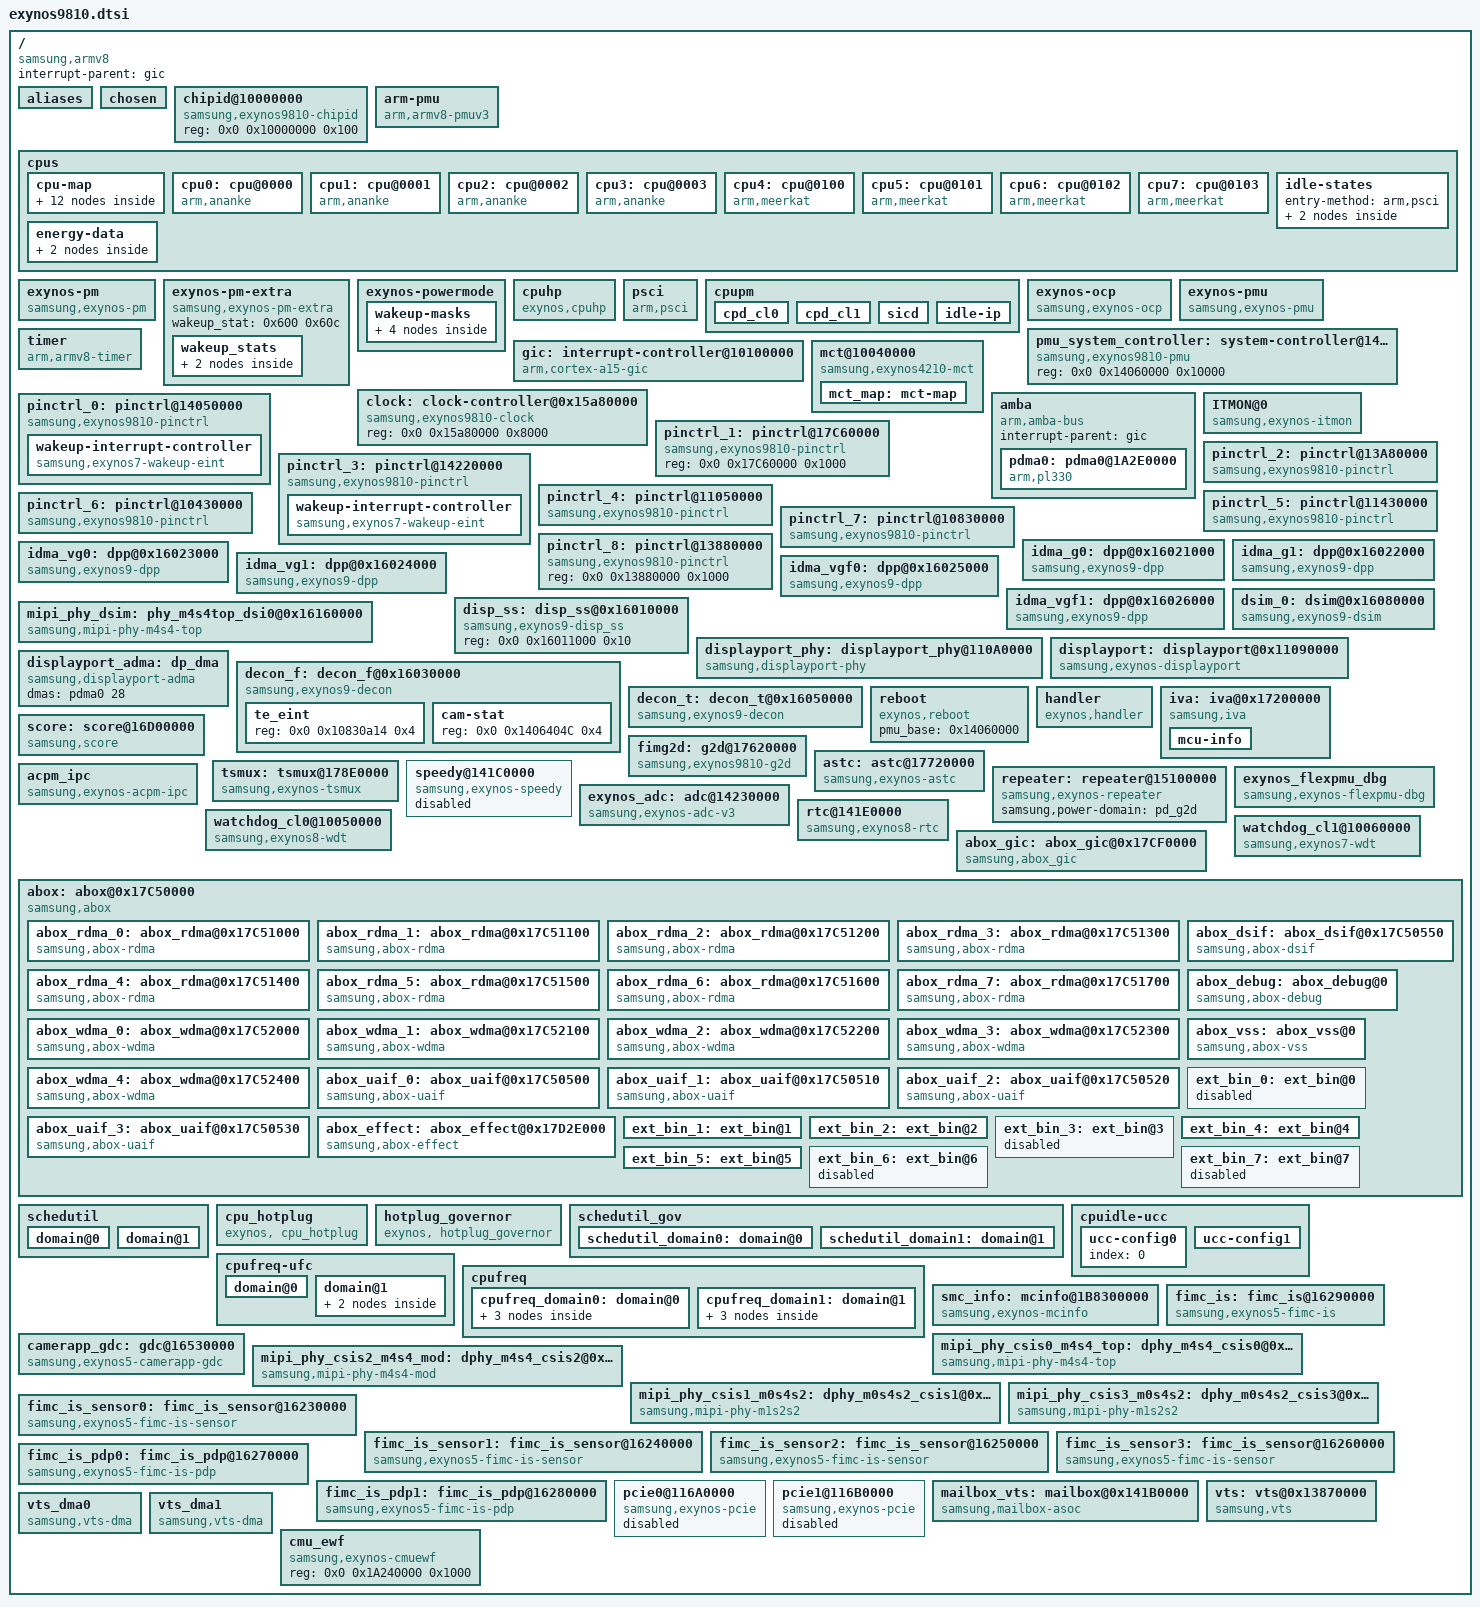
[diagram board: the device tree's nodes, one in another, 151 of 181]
/*
 * SAMSUNG EXYNOS9810 SoC device tree source
 *
 * Copyright (c) 2017 Samsung Electronics Co., Ltd.
 *		http://www.samsung.com
 *
 * SAMSUNG EXYNOS9810 SoC device nodes are listed in this file.
 * EXYNOS9810 based board files can include this file and provide
 * values for board specfic bindings.
 *
 * This program is free software; you can redistribute it and/or modify
 * it under the terms of the GNU General Public License version 2 as
 * published by the Free Software Foundation.
 */

#include <dt-bindings/clock/exynos9810.h>
#include <dt-bindings/interrupt-controller/exynos9810.h>
#include <dt-bindings/sysmmu/sysmmu.h>
#include <dt-bindings/soc/samsung/exynos9810.h>
#include <dt-bindings/thermal/thermal.h>
#include <dt-bindings/camera/fimc_is.h>
#include <dt-bindings/pci/pci.h>
#include <dt-bindings/ufs/ufs.h>
#include "exynos9810-pinctrl.dtsi"
#include "exynos9810-pm-domains.dtsi"
#include "exynos9810-etm.dtsi"
//#include "exynos9810-inputbooster.dtsi"
#include "exynos9810-debug.dtsi"
#include "exynos9810-mfc.dtsi"
#include "exynos9810-ufs.dtsi"
#include "exynos9810-security.dtsi"
#include "exynos9810-dm.dtsi"
#include "exynos9810-usb.dtsi"
#include "exynos9810-thermal.dtsi"
#include "exynos9810-pwm.dtsi"
#include "exynos9810-mmc.dtsi"
#include "exynos9810-devfreq.dtsi"
#include "exynos9810-power.dtsi"
#include "exynos9810-m2m.dtsi"
#include "exynos9810-gpu.dtsi"
#include "exynos9810-ems.dtsi"
#include "exynos9810-usi.dtsi"
#include "exynos9810-sysmmu.dtsi"

/ {
	compatible = "samsung,armv8", "samsung,exynos9810";
	interrupt-parent = <&gic>;
	#address-cells = <2>;
	#size-cells = <1>;

	aliases {
		pinctrl0 = &pinctrl_0;
		pinctrl1 = &pinctrl_1;
		pinctrl2 = &pinctrl_2;
		pinctrl3 = &pinctrl_3;
		pinctrl4 = &pinctrl_4;
		pinctrl5 = &pinctrl_5;
		pinctrl6 = &pinctrl_6;
		pinctrl7 = &pinctrl_7;
		pinctrl8 = &pinctrl_8;
		dpp0 = &idma_g0;
		dpp1 = &idma_g1;
		dpp2 = &idma_vg0;
		dpp3 = &idma_vg1;
		dpp4 = &idma_vgf0;
		dpp5 = &idma_vgf1;
		dsim0 = &dsim_0;
		displayport = &displayport;
		decon0 = &decon_f;
		decon2 = &decon_t;
		mfc0 = &mfc_0;
	};

	chosen: chosen {
		bootargs = "";
		linux,initrd-start = <0x84000000>;
		linux,initrd-end = <0x841FFFFF>;
	};

	chipid@10000000 {
		compatible = "samsung,exynos9810-chipid";
		reg = <0x0 0x10000000 0x100>;
	};

	arm-pmu {
		compatible = "arm,armv8-pmuv3";
		interrupts = <0 INTREQ__CPUCL1_PMUIRQ_0 4>,
			     <0 INTREQ__CPUCL1_PMUIRQ_1 4>,
			     <0 INTREQ__CPUCL1_PMUIRQ_2 4>,
			     <0 INTREQ__CPUCL1_PMUIRQ_3 4>,
			     <0 INTREQ__CPUCL0_PMUIRQ_0 4>,
			     <0 INTREQ__CPUCL0_PMUIRQ_1 4>,
			     <0 INTREQ__CPUCL0_PMUIRQ_2 4>,
			     <0 INTREQ__CPUCL0_PMUIRQ_3 4>;

		interrupt-affinity = <&cpu4>,
					<&cpu5>,
					<&cpu6>,
					<&cpu7>,
					<&cpu0>,
					<&cpu1>,
					<&cpu2>,
					<&cpu3>;			     
	};

	cpus {
		#address-cells = <2>;
		#size-cells = <0>;

		cpu-map {
			cluster0 {
				coregroup0 {
					core0 {
						cpu = <&cpu0>;
					};
					core1 {
						cpu = <&cpu1>;
					};
					core2 {
						cpu = <&cpu2>;
					};
					core3 {
						cpu = <&cpu3>;
					};
				};
			};

			cluster1 {
				coregroup0 {
					core0 {
						cpu = <&cpu4>;
					};
					core1 {
						cpu = <&cpu5>;
					};
					core2 {
						cpu = <&cpu6>;
					};
					core3 {
						cpu = <&cpu7>;
					};
				};
			};
		};

		cpu0: cpu@0000 {
			device_type = "cpu";
			compatible = "arm,ananke", "arm,armv8";
			reg = <0x0 0x0000>;
			enable-method = "psci";
			cpu-idle-states = <&BOOTCL_CPU_SLEEP>;
			sched-energy-data = <&ANANKE_ENERGY>;
		};
		cpu1: cpu@0001 {
			device_type = "cpu";
			compatible = "arm,ananke", "arm,armv8";
			reg = <0x0 0x0001>;
			enable-method = "psci";
			cpu-idle-states = <&BOOTCL_CPU_SLEEP>;
			sched-energy-data = <&ANANKE_ENERGY>;
		};
		cpu2: cpu@0002 {
			device_type = "cpu";
			compatible = "arm,ananke", "arm,armv8";
			reg = <0x0 0x0002>;
			enable-method = "psci";
			cpu-idle-states = <&BOOTCL_CPU_SLEEP>;
			sched-energy-data = <&ANANKE_ENERGY>;
		};
		cpu3: cpu@0003 {
			device_type = "cpu";
			compatible = "arm,ananke", "arm,armv8";
			reg = <0x0 0x0003>;
			enable-method = "psci";
			cpu-idle-states = <&BOOTCL_CPU_SLEEP>;
			sched-energy-data = <&ANANKE_ENERGY>;
		};
		cpu4: cpu@0100 {
			device_type = "cpu";
			compatible = "arm,meerkat", "arm,armv8";
			reg = <0x0 0x100>;
			enable-method = "psci";
			cpu-idle-states = <&NONBOOTCL_CPU_SLEEP>;
			sched-energy-data = <&MEERKAT_ENERGY>;
		};
		cpu5: cpu@0101 {
			device_type = "cpu";
			compatible = "arm,meerkat", "arm,armv8";
			reg = <0x0 0x101>;
			enable-method = "psci";
			cpu-idle-states = <&NONBOOTCL_CPU_SLEEP>;
			sched-energy-data = <&MEERKAT_ENERGY>;
		};
		cpu6: cpu@0102 {
			device_type = "cpu";
			compatible = "arm,meerkat", "arm,armv8";
			reg = <0x0 0x102>;
			enable-method = "psci";
			cpu-idle-states = <&NONBOOTCL_CPU_SLEEP>;
			sched-energy-data = <&MEERKAT_ENERGY>;
		};
		cpu7: cpu@0103 {
			device_type = "cpu";
			compatible = "arm,meerkat", "arm,armv8";
			reg = <0x0 0x103>;
			enable-method = "psci";
			cpu-idle-states = <&NONBOOTCL_CPU_SLEEP>;
			sched-energy-data = <&MEERKAT_ENERGY>;
		};
		idle-states {
			entry-method = "arm,psci";

			BOOTCL_CPU_SLEEP: bootcl-cpu-sleep {
				idle-state-name = "c2";
				compatible = "exynos,idle-state";
				arm,psci-suspend-param = <0x0010000>;
				entry-latency-us = <70>;
				exit-latency-us = <160>;
				min-residency-us = <2000>;
				status = "okay";
			};

			NONBOOTCL_CPU_SLEEP: nobootcl-cpu-sleep {
				idle-state-name = "c2";
				compatible = "exynos,idle-state";
				arm,psci-suspend-param = <0x0010000>;
				entry-latency-us = <235>;
				exit-latency-us = <220>;
				min-residency-us = <3500>;
				status = "okay";
			};
		};

		energy-data {
			ANANKE_ENERGY: ananke-energy {
				mips-per-mhz = <2776>;
				capacity-mips = <272>;
				power-coefficient = <160>;
				capacity-mips-s = <215>;
				power-coefficient-s = <130>;
				static-power-coefficient = <45>;

				capacity-weight = <1>;
				energy-weight = <1>;
			};
			MEERKAT_ENERGY: meerkat-energy {
				mips-per-mhz = <8012>;
				capacity-mips = <785>;
				power-coefficient = <800>;
				capacity-mips-s = <365>;
				power-coefficient-s = <506>;
				static-power-coefficient = <120>;

				capacity-weight = <1>;
				energy-weight = <3>;
			};
		};
	};

	exynos-pm {
		compatible = "samsung,exynos-pm";
		reg = <0x0 0x14050000 0x1000>,
		    <0x0 0x10101200 0x100>;
		reg-names = "gpio_alive_base",
				"gicd_ispendrn_base";
		num-eint = <34>;
		num-gic = <16>;
		suspend_mode_idx = <8>;		/* SYS_SLEEP */
		suspend_psci_idx = <133>;	/* PSCI_SYSTEM_SLEEP */
		cp_call_mode_idx = <10>;	/* SYS_SLEEP_AUD_ON */
		cp_call_psci_idx = <133>;	/* PSCI_SYSTEM_SLEEP */

		usbl2_suspend_available = <1>;	/* SYS_SLEEP_AUD_ON */
		usbl2_suspend_mode_idx = <12>;	/* SYS_SLEEP_AUD_ON */
		conn_req_offset = <0x00c0>;	/* PMU_ALIVE__CONNECT_REQ_STATUS */
	};

	exynos-pm-extra {
		compatible = "samsung,exynos-pm-extra";
		wakeup_stat = <0x600 0x60c>;

		wakeup_stats {
			wakeup_stat {
				ws-name =
					"RTC_ALARM",		/* [ 0] */
					"RTC_TICK",		/* [ 1] */
					"TRTC_ALARM",		/* [ 2] */
					"TRTC_TICK",		/* [ 3] */
					"SPARE",		/* [ 4] */
					"CMGP2PMU_AP_EINT0",	/* [ 5] */
					"CMGP2PMU_AP_EINT1",	/* [ 6] */
					"MAILBOX_APM2AP",	/* [ 7] */
					"MAILBOX_CP2AP",	/* [ 8] */
					"MAILBOX_VTS2AP",	/* [ 9] */
					"S_MAILBOX_CP2AP",	/* [10] */
					"VTS_WDT",		/* [11] */
					"EINT",			/* [12] */
					"EXT_PCIE_GEN2",	/* [13] */
					"PCIE_GEN2",		/* [14] */
					"USB_REWA",		/* [15] */
					"USBDP",		/* [16] */
					"MMC_CARD",		/* [17] */
					"TIMER";		/* [18] */
			};
			wakeup2_stat {
				ws-name =
					"UART_BT_CTSn",		/* [ 0] */
					"UART_BT_RXD",		/* [ 1] */
					"USB20_PHY_FS_VMINUS",	/* [ 2] */
					"USB20_PHY_FS_VPLUS";	/* [ 3] */
			};
		};
	};

	exynos-powermode {
		wakeup-masks {
			/*
			 * wakeup_mask configuration
			 *	        SICD          SICD_CPD      AFTR          STOP
			 *              LPD           LPA           ALPA          DSTOP
			 *              SLEEP         SLEEP_VTS_ON  SLEEP_AUD_ON  FAPO USB_L2
			 */
			wakeup-mask {
				mask = <0x400001E0>, <0x0>,        <0x0>,        <0x0>,
				       <0x0>,        <0x0>,        <0x0>,        <0x0>,
				       <0xD00F7E7E>, <0x500F7E7E>, <0x500F7E7E>, <0x0>, <0xD00D7E7E>;
				reg-offset = <0x610>;
			};
			wakeup-mask2 {
				mask = <0x0>,	     <0x0>, 	   <0x0>, 	 <0x0>,
				       <0x0>,        <0x0>,        <0x0>,        <0x0>,
				       <0xFFFF00FF>, <0xFFFF00FF>, <0xFFFF00FF>, <0x0>, <0xFFFF00FF>;
				reg-offset = <0x614>;
			};
			wakeup-mask3 {
				mask = <0x0>,	     <0x0>, 	   <0x0>, 	 <0x0>,
				       <0x0>,        <0x0>,        <0x0>,        <0x0>,
				       <0xFFFF00FF>, <0xFFFF00FF>, <0xFFFF00FF>, <0x0>, <0xFFFF00FF>;
				reg-offset = <0x618>;
			};
			wakeup-mask4 {
				mask = <0x0>,	     <0x0>, 	   <0x0>,	 <0x0>,
				       <0x0>,        <0x0>,        <0x0>,        <0x0>,
				       <0x0>, 	     <0x0>, 	   <0x0>,        <0x0>, <0x0>;
				reg-offset = <0x644>;
			};
		};
	};

	cpuhp {
		compatible = "exynos,cpuhp";
	};

	psci {
		compatible = "arm,psci";
		method = "smc";
		cpu_suspend = <0xC4000001>;
		cpu_off = <0x84000002>;
		cpu_on = <0xC4000003>;
	};

	cpupm {
		#define POWERMODE_TYPE_CLUSTER	0
		#define POWERMODE_TYPE_SYSTEM	1

		cpd_cl0 {
			device_type = "cpupm";
			target-residency = <10000>;
			psci-index = <128>;
			type = <POWERMODE_TYPE_CLUSTER>;
			siblings = "0-3";
		};

		cpd_cl1 {
			device_type = "cpupm";
			target-residency = <10000>;
			psci-index = <128>;
			type = <POWERMODE_TYPE_CLUSTER>;
			siblings = "4-7";
			entry-allowed = "4-7";
		};

		sicd {
			device_type = "cpupm";
			target-residency = <10000>;	/* us */
			psci-index = <256>;
			type = <POWERMODE_TYPE_SYSTEM>;
			siblings = "0-7";
			entry-allowed = "0-3";
			system-idle;
		};

		idle-ip {
			idle-ip-list =
				  "104c0000.pwm",		/* [ 0] pwm      */
			          "14230000.adc",		/* [ 1] adc      */
			          "10860000.hsi2c",		/* [ 2] hsi2c_0  */
			          "10870000.hsi2c",		/* [ 3] hsi2c_1  */
			          "10880000.hsi2c",		/* [ 4] hsi2c_2  */
			          "10890000.hsi2c",		/* [ 5] hsi2c_3  */
			          "10450000.hsi2c",		/* [ 6] hsi2c_4  */
			          "10460000.hsi2c",		/* [ 7] hsi2c_5  */
			          "10470000.hsi2c",		/* [ 8] hsi2c_6  */
			          "10480000.hsi2c",		/* [ 9] hsi2c_7  */
			          "10490000.hsi2c",		/* [10] hsi2c_8  */
			          "104a0000.hsi2c",		/* [11] hsi2c_9  */
			          "104b0000.hsi2c",		/* [12] hsi2c_10 */
			          "104c0000.hsi2c",		/* [13] hsi2c_11 */
			          "104d0000.hsi2c",		/* [14] hsi2c_12 */
			          "104e0000.hsi2c",		/* [15] hsi2c_13 */
			          "104f0000.hsi2c",		/* [16] hsi2c_14 */
			          "10500000.hsi2c",		/* [17] hsi2c_15 */
			          "108a0000.hsi2c",		/* [18] hsi2c_16 */
			          "108b0000.hsi2c",		/* [19] hsi2c_17 */
			          "108c0000.hsi2c",		/* [20] hsi2c_18 */
			          "108d0000.hsi2c",		/* [21] hsi2c_19 */
			          "108e0000.hsi2c",		/* [22] hsi2c_20 */
			          "108f0000.hsi2c",		/* [23] hsi2c_21 */
			          "10900000.hsi2c",		/* [24] hsi2c_22 */
			          "10910000.hsi2c",		/* [25] hsi2c_23 */
			          "10920000.hsi2c",		/* [26] hsi2c_24 */
			          "10930000.hsi2c",		/* [27] hsi2c_25 */
			          "10940000.hsi2c",		/* [28] hsi2c_26 */
			          "10950000.hsi2c",		/* [29] hsi2c_27 */
			          "10520000.hsi2c",		/* [30] hsi2c_28 */
			          "10530000.hsi2c",		/* [31] hsi2c_29 */
			          "10540000.hsi2c",		/* [32] hsi2c_30 */
			          "10550000.hsi2c",		/* [33] hsi2c_31 */
			          "10560000.hsi2c",		/* [34] hsi2c_32 */
			          "10570000.hsi2c",		/* [35] hsi2c_33 */
			          "14300000.hsi2c",		/* [36] hsi2c_34 */
			          "14310000.hsi2c",		/* [37] hsi2c_35 */
			          "14320000.hsi2c",		/* [38] hsi2c_36 */
			          "14330000.hsi2c",		/* [39] hsi2c_37 */
			          "14340000.hsi2c",		/* [40] hsi2c_38 */
			          "14350000.hsi2c",		/* [41] hsi2c_39 */
			          "14360000.hsi2c",		/* [42] hsi2c_40 */
			          "14370000.hsi2c",		/* [43] hsi2c_41 */
			          "10850000.spi",		/* [44] spi_0    */
			          "10450000.spi",		/* [45] spi_1    */
			          "10470000.spi",		/* [46] spi_2    */
			          "10490000.spi",		/* [47] spi_3    */
			          "104b0000.spi",		/* [48] spi_4    */
			          "104d0000.spi",		/* [49] spi_5    */
			          "104f0000.spi",		/* [50] spi_6    */
			          "108a0000.spi",		/* [51] spi_7    */
			          "108c0000.spi",		/* [52] spi_8    */
			          "108e0000.spi",		/* [53] spi_9    */
			          "10900000.spi",		/* [54] spi_10   */
			          "10920000.spi",		/* [55] spi_11   */
			          "10940000.spi",		/* [56] spi_12   */
			          "10520000.spi",		/* [57] spi_13   */
			          "10540000.spi",		/* [58] spi_14   */
			          "10560000.spi",		/* [59] spi_15   */
			          "14300000.spi",		/* [60] spi_16   */
			          "14320000.spi",		/* [61] spi_17   */
			          "14340000.spi",		/* [62] spi_18   */
			          "14360000.spi",		/* [63] spi_19   */
			          "11120000.ufs",		/* [64] ufs      */
			          "11500000.dwmmc2",		/* [65] dwmmc2   */
			          "10c00000.usb",		/* [66] usb      */
			          "141a0000.mailbox",		/* [67] mailbox  */
			          "116a0000.pcie0",		/* [68] pcie0    */
			          "116b0000.pcie1",		/* [69] pcie1    */
			          "pd-aud",			/* [70] pd-aud	 */
			          "pd-dcf",			/* [71] pd-dcf   */
			          "pd-dcpost",			/* [72] pd-dcpost*/
			          "pd-dcrd",			/* [73] pd-dcrd  */
			          "pd-dpu",			/* [74] pd-dpu   */
			          "pd-dspm",			/* [75] pd-dspm  */
			          "pd-dsps",			/* [76] pd-dsps  */
			          "pd-g2d",			/* [77] pd-g2d   */
			          "pd-embedded_g3d",		/* [78] pd-embedded_g3d */
			          "pd-isppre",			/* [79] pd-isppre */
			          "pd-isphq",			/* [80] pd-isphq */
			          "pd-isplp",			/* [81] pd-isplp */
			          "pd-iva",			/* [82] pd-iva   */
			          "pd-mfc",			/* [83] pd-mfc   */
			          "pd-vts",			/* [84] pd-vts   */
			          "11090000.displayport",	/* [85] displayport */
			          "bluetooth";			/* [86] bluetooth */

			fix-idle-ip = "acpm_dvfs";
			fix-idle-ip-index = <96>;

			idle-ip-mask = <0>,  <1>,  <2>,  <3>,  <4>,  <5>,  <6>,  <7>,  <8>,  <9>,
					     <10>, <11>, <12>, <13>, <14>, <15>, <16>, <17>, <18>, <19>,
					     <20>, <21>, <22>, <23>, <24>, <25>, <26>, <27>, <28>, <29>,
					     <30>, <31>, <32>, <33>, <34>, <35>, <36>, <37>, <38>, <39>,
					     <40>, <41>, <42>, <43>, <44>, <45>, <46>, <47>, <48>, <49>,
					     <50>, <51>, <52>, <53>, <54>, <55>, <56>, <57>, <58>, <59>,
					     <60>, <61>, <62>, <63>, <64>, <65>, <66>, <67>, <68>, <69>,
					                             <74>, <75>, <76>, <77>, <78>, <79>,
					     <80>, <81>, <82>, <83>,       <85>, <86>, <96>;
		};
	};

	exynos-ocp {
		compatible = "samsung,exynos-ocp";

		interrupts = <0 INTREQ__CPUCL1_GCUIRQ 0>;
		sibling-cpus = "4-7";
		down-step = <1>;

		max-freq-wo-ocp = <1794000>;

		release-mode = <1>;		/* 0 : current meter, 1 : cpu utilization */
		release-threshold = <50>;	/* @current meter : current(A), @cpu load : capacity ratio(%) */
		release-duration = <15>;	/* msec */
	};

	exynos-pmu {
		compatible = "samsung,exynos-pmu";
		samsung,syscon-phandle = <&pmu_system_controller>;
		reg = <0x0 0x14060000 0x10000>;
		reg-names = "pmu_alive";
	};

	pmu_system_controller: system-controller@14060000 {
		compatible = "samsung,exynos9810-pmu", "syscon";
		reg = <0x0 0x14060000 0x10000>;
	};

	gic:interrupt-controller@10100000 {
		compatible = "arm,cortex-a15-gic", "arm,cortex-a9-gic";
		#interrupt-cells = <3>;
		#address-cells = <0>;
		interrupt-controller;
		reg =	<0x0 0x10101000 0x1000>,
			<0x0 0x10102000 0x1000>,
			<0x0 0x10104000 0x2000>,
			<0x0 0x10106000 0x2000>;
		interrupts = <1 9 0xf04>;
	};

	timer {
		compatible = "arm,armv8-timer";
		interrupts = <GIC_PPI 13
				(GIC_CPU_MASK_SIMPLE(8) | IRQ_TYPE_LEVEL_LOW)>,
			     <GIC_PPI 14
				(GIC_CPU_MASK_SIMPLE(8) | IRQ_TYPE_LEVEL_LOW)>,
			     <GIC_PPI 11
				(GIC_CPU_MASK_SIMPLE(8) | IRQ_TYPE_LEVEL_LOW)>,
			     <GIC_PPI 10
				(GIC_CPU_MASK_SIMPLE(8) | IRQ_TYPE_LEVEL_LOW)>;
	        clock-frequency = <26000000>;
		use-clocksource-only;
		use-physical-timer;
	};

	clock: clock-controller@0x15a80000 {
		compatible = "samsung,exynos9810-clock";
		reg = <0x0 0x15a80000 0x8000>;
		#clock-cells = <1>;
	};

	mct@10040000 {
		compatible = "samsung,exynos4210-mct";
		reg = <0x0 0x10040000 0x800>;
		interrupt-controller;
		#interrupt-cells = <1>;
		interrupt-parent = <&mct_map>;
		interrupts =	<0>, <1>, <2>, <3>,
				<4>, <5>, <6>, <7>,
				<8>, <9>, <10>, <11>;
		clocks = <&clock OSCCLK>, <&clock GATE_MCT>;
		clock-names = "fin_pll", "mct";
		use-clockevent-only;

		mct_map: mct-map {
			#interrupt-cells = <1>;
			#address-cells = <0>;
			#size-cells = <0>;
			interrupt-map = <0 &gic 0 INTREQ__MCT_G0 0>,
					<1 &gic 0 INTREQ__MCT_G1 0>,
					<2 &gic 0 INTREQ__MCT_G2 0>,
					<3 &gic 0 INTREQ__MCT_G3 0>,
					<4 &gic 0 INTREQ__MCT_L0 0>,
					<5 &gic 0 INTREQ__MCT_L1 0>,
					<6 &gic 0 INTREQ__MCT_L2 0>,
					<7 &gic 0 INTREQ__MCT_L3 0>,
					<8 &gic 0 INTREQ__MCT_L4 0>,
					<9 &gic 0 INTREQ__MCT_L5 0>,
					<10 &gic 0 INTREQ__MCT_L6 0>,
					<11 &gic 0 INTREQ__MCT_L7 0>;
		};
	};

	/* DMA */
	amba {
		#address-cells = <2>;
		#size-cells = <1>;
		compatible = "arm,amba-bus";
		interrupt-parent = <&gic>;
		ranges;

		pdma0: pdma0@1A2E0000 {
			compatible = "arm,pl330", "arm,primecell";
			reg = <0x0 0x1A2E0000 0x1000>;
			interrupts = <0 INTREQ__PDMA0 0>;
			clocks = <&clock GATE_PDMA0>;
			clock-names = "apb_pclk";
			#dma-cells = <1>;
			#dma-channels = <8>;
			#dma-requests = <32>;
			#dma-multi-irq = <1>;
			dma-arwrapper = <0x1A2E4400>,
					<0x1A2E4420>,
					<0x1A2E4440>,
					<0x1A2E4460>,
					<0x1A2E4480>,
					<0x1A2E44A0>,
					<0x1A2E44C0>,
					<0x1A2E44E0>;
			dma-awwrapper = <0x1A2E4404>,
					<0x1A2E4424>,
					<0x1A2E4444>,
					<0x1A2E4464>,
					<0x1A2E4484>,
					<0x1A2E44A4>,
					<0x1A2E44C4>,
					<0x1A2E44E4>;
			dma-instwrapper = <0x1A2E4500>;
			dma-mask-bit = <36>;
			coherent-mask-bit = <36>;
		};
	};

	ITMON@0 {
		compatible = "samsung,exynos-itmon";
		interrupts = <0 INTREQ__TREX_DEBUG 0>,  /* DATA_BUS_C  */
			     <0 INTREQ__TREX_D_CORE_debugInterrupt 0>, /* DATA_CORE   */
			     <0 INTREQ__TREX_P0_CORE_debugInterrupt 0>, /* PERI_CORE_0 */
			     <0 INTREQ__TREX_P_DEBUG 0>,  /* PERI_BUS_C  */
			     <0 INTREQ__TREX_P1_CORE_debugInterrupt 0>, /* PERI_CORE_1 */
			     <0 INTREQ__TREX_P_BUS1_DEBUG 0>;  /* PERI_BUS_1  */
	};

	/* ALIVE */
	pinctrl_0: pinctrl@14050000 {
		compatible = "samsung,exynos9810-pinctrl";
		reg = <0x0 0x14050000 0x1000>;
		interrupts = <0 INTREQ__EINT0 0>, <0 INTREQ__EINT1 0>, <0 INTREQ__EINT2 0>,
			     <0 INTREQ__EINT3 0>, <0 INTREQ__EINT4 0>, <0 INTREQ__EINT5 0>,
			     <0 INTREQ__EINT6 0>, <0 INTREQ__EINT7 0>, <0 INTREQ__EINT8 0>,
			     <0 INTREQ__EINT9 0>, <0 INTREQ__EINT10 0>, <0 INTREQ__EINT11 0>,
			     <0 INTREQ__EINT12 0>, <0 INTREQ__EINT13 0>, <0 INTREQ__EINT14 0>,
			     <0 INTREQ__EINT15 0>, <0 INTREQ__EINT16 0>, <0 INTREQ__EINT17 0>,
			     <0 INTREQ__EINT18 0>, <0 INTREQ__EINT19 0>, <0 INTREQ__EINT20 0>,
			     <0 INTREQ__EINT21 0>, <0 INTREQ__EINT22 0>, <0 INTREQ__EINT23 0>,
			     <0 INTREQ__EINT24 0>, <0 INTREQ__EINT25 0>, <0 INTREQ__EINT26 0>,
			     <0 INTREQ__EINT27 0>, <0 INTREQ__EINT28 0>, <0 INTREQ__EINT29 0>,
			     <0 INTREQ__EINT30 0>, <0 INTREQ__EINT31 0>, <0 INTREQ__EINT32 0>,
			     <0 INTREQ__EINT33 0>;

		wakeup-interrupt-controller {
			compatible = "samsung,exynos7-wakeup-eint";
		};
	};

	/* AUD */
	pinctrl_1: pinctrl@17C60000{
		compatible = "samsung,exynos9810-pinctrl";
		reg = <0x0 0x17C60000 0x1000>;
	};

	/* CHUB */
	pinctrl_2: pinctrl@13A80000{
		compatible = "samsung,exynos9810-pinctrl";
		reg = <0x0 0x13A80000 0x1000>;
		interrupts = <0 INTREQ__GPIO_CHUB 0>;
	};

	/* CMGP */
	pinctrl_3: pinctrl@14220000{
		compatible = "samsung,exynos9810-pinctrl";
		reg = <0x0 0x14220000 0x1000>;
		interrupts = <0 INTREQ__EXT_INTM0_0 0>, <0 INTREQ__EXT_INTM0_1 0>,
			     <0 INTREQ__EXT_INTM0_2 0>, <0 INTREQ__EXT_INTM0_3 0>,
			     <0 INTREQ__EXT_INTM0_4 0>, <0 INTREQ__EXT_INTM0_5 0>,
			     <0 INTREQ__EXT_INTM0_6 0>, <0 INTREQ__EXT_INTM0_7 0>,
			     <0 INTREQ__EXT_INTM1_0 0>, <0 INTREQ__EXT_INTM1_1 0>,
			     <0 INTREQ__EXT_INTM1_2 0>, <0 INTREQ__EXT_INTM1_3 0>,
			     <0 INTREQ__EXT_INTM1_4 0>, <0 INTREQ__EXT_INTM1_5 0>,
			     <0 INTREQ__EXT_INTM1_6 0>, <0 INTREQ__EXT_INTM1_7 0>,
			     <0 INTREQ__EXT_INTM4_0 0>, <0 INTREQ__EXT_INTM4_1 0>,
			     <0 INTREQ__EXT_INTM4_2 0>, <0 INTREQ__EXT_INTM4_3 0>;

		wakeup-interrupt-controller {
			compatible = "samsung,exynos7-wakeup-eint";
		};
	};

	/* FSYS0 */
	pinctrl_4: pinctrl@11050000 {
		compatible = "samsung,exynos9810-pinctrl";
		reg = <0x0 0x11050000 0x1000>;
		interrupts = <0 INTREQ__GPIO_FSYS0 0>;
	};

	/* FSYS1 */
	pinctrl_5: pinctrl@11430000 {
		compatible = "samsung,exynos9810-pinctrl";
		reg = <0x0 0x11430000 0x1000>;
		interrupts = <0 INTREQ__GPIO_FSYS1 0>;
	};

	/* PERIC0 */
	pinctrl_6: pinctrl@10430000 {
		compatible = "samsung,exynos9810-pinctrl";
		reg = <0x0 0x10430000 0x1000>;
		interrupts = <0 INTREQ__GPIO_PERIC0 0>;
	};

	/* PERIC1 */
	pinctrl_7: pinctrl@10830000 {
		compatible = "samsung,exynos9810-pinctrl";
		reg = <0x0 0x10830000 0x1000>;
		interrupts = <0 INTREQ__GPIO_PERIC1 0>;
	};

	/* VTS */
	pinctrl_8: pinctrl@13880000 {
		compatible = "samsung,exynos9810-pinctrl";
		reg = <0x0 0x13880000 0x1000>;
	};

	idma_g0: dpp@0x16021000 {
		compatible = "samsung,exynos9-dpp";
		#pb-id-cells = <3>;
		/* DPP, DPU_DMA, DPU_DMA_COMMON */
		reg = <0x0 0x16021000 0x1000>, <0x0 0x16071000 0x1000>, <0x0 0x16070000 0x110>;
		/* DPU_DMA IRQ, DPP IRQ */
		interrupts = <0 INTREQ__DPU_DMA_G0 0>, <0 INTREQ__DPU_DPP_G0 0>;
		dpp,hold-rpm-on-boot;
		/* power domain */
		samsung,power-domain = <&pd_dpu>;
	};

	idma_g1: dpp@0x16022000 {
		compatible = "samsung,exynos9-dpp";
		#pb-id-cells = <3>;
		reg = <0x0 0x16022000 0x1000>, <0x0 0x16072000 0x1000>;
		interrupts = <0 INTREQ__DPU_DMA_G1 0>, <0 INTREQ__DPU_DPP_G1 0>;

		/* power domain */
		samsung,power-domain = <&pd_dpu>;
	};

	idma_vg0: dpp@0x16023000 {
		compatible = "samsung,exynos9-dpp";
		#pb-id-cells = <3>;
		reg = <0x0 0x16023000 0x1000>, <0x0 0x16073000 0x1000>;
		interrupts = <0 INTREQ__DPU_DMA_VG0 0>, <0 INTREQ__DPU_DPP_VG0 0>;

		/* power domain */
		samsung,power-domain = <&pd_dpu>;
	};

	idma_vg1: dpp@0x16024000 {
		compatible = "samsung,exynos9-dpp";
		#pb-id-cells = <3>;
		reg = <0x0 0x16024000 0x1000>, <0x0 0x16074000 0x1000>;
		interrupts = <0 INTREQ__DPU_DMA_VG1 0>, <0 INTREQ__DPU_DPP_VG1 0>;

		/* power domain */
		samsung,power-domain = <&pd_dpu>;
	};

	idma_vgf0: dpp@0x16025000 {
		compatible = "samsung,exynos9-dpp";
		#pb-id-cells = <3>;
		reg = <0x0 0x16025000 0x1000>, <0x0 0x16075000 0x1000>;
		interrupts = <0 INTREQ__DPU_DMA_VGF 0>, <0 INTREQ__DPU_DPP_VGF0 0>;

		/* power domain */
		samsung,power-domain = <&pd_dpu>;
	};

	idma_vgf1: dpp@0x16026000 {
		compatible = "samsung,exynos9-dpp";
		#pb-id-cells = <3>;
		reg = <0x0 0x16026000 0x1000>, <0x0 0x16076000 0x1000>;
		interrupts = <0 INTREQ__DPU_DMA_VGRF 0>, <0 INTREQ__DPU_DPP_VGF1 0>;

		/* power domain */
		samsung,power-domain = <&pd_dpu>;
	};

	disp_ss: disp_ss@0x16010000 {
		compatible = "samsung,exynos9-disp_ss";
		reg = <0x0 0x16011000 0x10>;
	};

	mipi_phy_dsim: phy_m4s4top_dsi0@0x16160000 {
		compatible = "samsung,mipi-phy-m4s4-top";
		samsung,pmu-syscon = <&pmu_system_controller>;
		isolation = <0x070C>;
		/* PHY reset be controlled from DSIM */
		/* reg = <0x0 0x12821008 0x4>; */
		/* reset = <0 1>; */
		/* init = <4 5>; */ /* PHY reset control path bit of SYSREG */
		owner = <0>; /* 0: DSI,  1: CSI */
		#phy-cells = <1>;
	};

	dsim_0: dsim@0x16080000 {
		compatible = "samsung,exynos9-dsim";
		reg = <0x0 0x16080000 0x100>, <0x0 0x16160000 0x4000>;
		interrupts = <0 INTREQ__DPU_DSIM0 0>;
		iommus = <&sysmmu_dpu0>, <&sysmmu_dpu1>, <&sysmmu_dpu2>;

		/* clock */
		clock-names = "aclk";
		clocks = <&clock GATE_DPU>;

		phys = <&mipi_phy_dsim 0>;
		phy-names = "dsim_dphy";

		/* power domain */
		samsung,power-domain = <&pd_dpu>;
	};

	displayport_phy: displayport_phy@110A0000 {
		compatible = "samsung,displayport-phy";
		samsung,pmu-syscon = <&pmu_system_controller>;
		isolation = <0x0704>;
		#phy-cells = <1>;
	};

	displayport: displayport@0x11090000 {
		compatible = "samsung,exynos-displayport";
		reg = <0x0 0x11090000 0xFFFF>;
		interrupts = <0 INTREQ__DP_LINK 0>;
		iommus = <&sysmmu_dpu0>, <&sysmmu_dpu1>, <&sysmmu_dpu2>;

		/* clock */
		clock-names = "aclk";
		clocks = <&clock GATE_DPU>;

		phys = <&displayport_phy 0>;
		phy-names = "displayport_phy";

		/* power domain */
		samsung,power-domain = <&pd_dpu>;
	};

	displayport_adma: dp_dma {
		compatible = "samsung,displayport-adma";

		/* dma-mode; */
		dmas = <&pdma0 28>;
		dma-names = "tx";
	};

	decon_f: decon_f@0x16030000 {
		compatible = "samsung,exynos9-decon"; /* exynos9810 */
		#pb-id-cells = <4>;
		reg = <0x0 0x16030000 0x10000>;

		/* interrupt num : FRAME_START, FRMAE_DONE, EXTRA, GPIO_PERIC1(EXT_INT_TE: GPD0[0]) */
		interrupts = <0 INTREQ__DPU_DECON0_FRAME_START 0>,
			     <0 INTREQ__DPU_DECON0_FRAME_DONE 0>,
			     <0 INTREQ__DPU_DECON0_EXTRA 0>,
			     <0 INTREQ__GPIO_PERIC1 0>;

		/* pinctrl */
		pinctrl-names = "hw_te_on", "hw_te_off";
		pinctrl-0 = <&decon_f_te_on>;
		pinctrl-1 = <&decon_f_te_off>;

		/* power domain */
		samsung,power-domain = <&pd_dpu>;

		max_win = <6>;
		default_win = <5>;
		default_idma = <0>;
		psr_mode = <2>;         /* 0: video mode, 1: DP command mode, 2: MIPI command mode */
		trig_mode = <0>;        /* 0: hw trigger, 1: sw trigger */
		dsi_mode = <0>;         /* 0: single dsi, 1: dual dsi */

		/* 0: DSI, 1: eDP, 2:HDMI, 3: WB */
		out_type = <0>;
		/* 0: DSI0, 1: DSI1, 2: DSI2 */
		out_idx = <0>;

		#address-cells = <2>;
		#size-cells = <1>;
		ranges;

		/* EINT for TE */
		gpios = <&gpd0 0 0xf>;
		/* sw te pending register */
		te_eint {
			/* NWEINT_GPD0_PEND */
			reg = <0x0 0x10830a14 0x4>;
		};

		cam-stat {
			/* ISPPRE_STATUS(0x1406404C), ISPHQ_STATUS(0x14064054), ISPLP_STATUS(0x1406405C) */
			reg = <0x0 0x1406404C 0x4>;
		};
	};

	decon_t: decon_t@0x16050000 {
		compatible = "samsung,exynos9-decon"; /* exynos9810 */
		#pb-id-cells = <4>;
		reg = <0x0 0x16050000 0x10000>;

		/* interrupt num : FRAME_START, FRMAE_DONE, EXTRA */
		interrupts = <0 INTREQ__DPU_DECON2_FRAME_START 0>,
			     <0 INTREQ__DPU_DECON2_FRAME_DONE 0>,
			     <0 INTREQ__DPU_DECON2_EXTRA 0>;

		/* power domain */
		samsung,power-domain = <&pd_dpu>;

		max_win = <6>;
		default_win = <4>;
		default_idma = <1>;
		psr_mode = <0>;         /* 0: video mode, 1: DP command mode, 2: MIPI command mode */
		trig_mode = <0>;        /* 0: hw trigger, 1: sw trigger */
		dsi_mode = <0>;         /* 0: single dsi, 1: dual dsi */

		/* 0: DSI, 1: eDP, 2:DP */
		out_type = <2>;
		/* 0: DSI0, 1: DSI1, 2: DSI2 */
		out_idx = <0>;

		#address-cells = <2>;
		#size-cells = <1>;
		ranges;
	};

	reboot {
		compatible = "exynos,reboot";
		pmu_base = <0x14060000>;
	};

	handler {
		compatible = "exynos,handler";
		interrupts = <0 INTREQ__CPUCL0_ERRIRQ_0 0>, /* CPUCL0 L3 ECC */
			     <0 INTREQ__CPUCL0_ERRIRQ_1 0>, /* CPUCL0_0 L1 ECC */
			     <0 INTREQ__CPUCL0_ERRIRQ_2 0>, /* CPUCL0_1 L1 ECC */
			     <0 INTREQ__CPUCL0_ERRIRQ_3 0>, /* CPUCL0_2 L1 ECC */
			     <0 INTREQ__CPUCL0_ERRIRQ_4 0>, /* CPUCL0_3 L1 ECC */
			     <0 INTREQ__CPUCL1_INTERRIRQ 0>; /* CPUCL1 L2, L3 ECC */
	};

	iva: iva@0x17200000 {
		compatible = "samsung,iva";
		reg = <0x0 0x17200000 0x200000>;

		iommus = <&sysmmu_iva>;

		interrupt-names = "iva_mbox_irq";
		interrupts = <0 INTREQ__BLK_IVA_IVA_iva_ap_irq_aq_0 0>;

		clocks = <&clock GATE_IVA>;
		clock-names = "clk_iva";
		samsung,power-domain = <&pd_iva>;
		dvfs-dev = <&devfreq_6>;
		qos_rate = <534000>;

		mcu-info {
			mem_size = <0x20000>;
			shmem_size = <0x1000>;
			print_delay = <0>;     /* us */
		};
	};

	score: score@16D00000 {
		compatible = "samsung,score";
		dma-coherent;
		reg = <0x0 0x16D00000 0x100000>;
		interrupts = <0 222 0>;

		clocks = <&clock GATE_SCORE_MASTER>, <&clock GATE_SCORE_KNIGHT>;
		clock-names = "dspm", "dsps";
		samsung,power-domain = <&pd_dsps>;

		iommus = <&sysmmu_score0>, <&sysmmu_score1>;
		qos_table = <534000 467000 336000 168000 34000>;
		default_qos = <534000>;
	};

	fimg2d: g2d@17620000 {
		compatible = "samsung,exynos9810-g2d";
		reg = <0x0 0x17620000 0x9000>;
		interrupts = <0 INTREQ__G2D 0>;
		clock-names = "gate";
		clocks = <&clock GATE_G2D>;
		samsung,power-domain = <&pd_g2d>;
		iommus = <&sysmmu_g2d0>, <&sysmmu_g2d1>;
		hw_ppc =
			/* sc_up none x1 x1/4 x1/9 x1/16 */
			<3400 3100 2200 3600 5100 7000 /* rgb32 non-rotated */
			3300 2700 2000 3000 5200 6500 /* rgb32 rotated */
			3000 2900 2600 3400 5100 11900 /* yuv2p non-rotated */
			3200 2000 1900 3300 5200 7000 /* yuv2p rotated */
			2400 1900 1900 2700 3100 4100 /* 8+2 non-rotated */
			2500 900 900 2200 2900 3700 /* 8+2 rotated */
			3800>; /* colorfill */

		g2d_dvfs_table = <534000 711000
				400000 534000
				336000 400000
				267000 356000
				178000 200000
				107000 134000
				>;
		dma-coherent;
	};

	astc: astc@17720000 {
		compatible = "samsung,exynos-astc";
		dma-coherent;
		reg = <0x0 0x17720000 0x1000>;
		interrupts = <0 INTREQ__ASTC 0>;
		clocks = <&clock GATE_ASTC>;
		clock-names = "gate";
		iommus = <&sysmmu_g2d2>;
		/* ASTC IP uses 533000, not 534000 */
		astc,int_qos_minlock = <533000>;
		samsung,power-domain = <&pd_g2d>;
	};

	tsmux: tsmux@178E0000 {
		compatible = "samsung,exynos-tsmux";
		reg = <0x0 0x178E0000 0x1000>;
		interrupts = <0 INTREQ__WFD 0>;
		iommus = <&sysmmu_mfc1>;
		/* power domain */
		samsung,power-domain = <&pd_mfc>;
	};

	repeater: repeater@15100000 {
		compatible = "samsung,exynos-repeater";
		/* power domain */
		samsung,power-domain = <&pd_g2d>;
	};

	speedy@141C0000 {
		compatible = "samsung,exynos-speedy";
		reg = <0x0 0x141C0000 0x2000>;
		interrupts = <0 INTREQ__SPEEDY_APM 0>;
		#address-cells = <1>;
		#size-cells = <0>;
		pinctrl-names = "default";
		pinctrl-0 = <&speedy_bus>;
#if 0
		clocks = <&clock GATE_SPEEDY_BATCHER_WRAP_BATCHER_AP>;
		clock-names = "gate_speedy";
#endif
		status = "disabled";
	};

	acpm_ipc {
		compatible = "samsung,exynos-acpm-ipc";
		#address-cells = <2>;
		#size-cells = <1>;
		interrupts = <0 INTREQ__MAILBOX_APM2AP 0>;	/* AP2APM MAILBOX SPI NUM*/
		reg = <0x0 0x14100000 0x1000>,		/* AP2APM MAILBOX */
			<0x0 0x2039000 0x30000>;	/* APM SRAM */
		initdata-base = <0x7F00>;
		num-timestamps = <32>;
		debug-log-level = <0>;
		logging-period = <500>;
		dump-base = <0x203C000>;
		dump-size = <0x1D000>;			/* 116KB */
	};

	exynos_flexpmu_dbg {
		compatible = "samsung,exynos-flexpmu-dbg";
		#address-cells = <2>;
		#size-cells = <1>;
		data-base = <0x204F800>;
		data-size = <0x400>;
	};

	exynos_adc: adc@14230000 {
		compatible = "samsung,exynos-adc-v3";
		reg = <0x0 0x14230000 0x100>;
		interrupts = <0 INTREQ__ADC_CMGP_S0 0>;
		#io-channel-cells = <1>;
		io-channel-ranges;
		clocks = <&clock GATE_ADC_CMGP>;
		clock-names = "gate_adcif";
	};

	rtc@141E0000 {
		compatible = "samsung,exynos8-rtc";
		reg = <0x0 0x141E0000 0x100>;
		interrupts = <0 INTREQ__RTC_ALARM_INT 0>, <0 INTREQ__RTC_TIC_INT_0 0>;
	};

	watchdog_cl0@10050000 {
		compatible = "samsung,exynos8-wdt";
		reg = <0x0 0x10050000 0x100>;
		interrupts = <0 INTREQ__WDT_CLUSTER0 0>;
		clocks = <&clock OSCCLK>, <&clock UMUX_CLKCMU_PERIS_BUS>;
		clock-names = "rate_watchdog", "gate_watchdog";
		timeout-sec = <30>;
		samsung,syscon-phandle = <&pmu_system_controller>;
		index = <0>; /* if little cluster then index is 0 */
	};

	watchdog_cl1@10060000 {
		compatible = "samsung,exynos7-wdt";
		reg = <0x0 0x10060000 0x100>;
		interrupts = <0 INTREQ__WDT_CLUSTER1 0>;
		clocks = <&clock OSCCLK>, <&clock UMUX_CLKCMU_PERIS_BUS>;
		clock-names = "rate_watchdog", "gate_watchdog";
		timeout-sec = <20>;
		samsung,syscon-phandle = <&pmu_system_controller>;
		index = <1>; /* if big cluster then index is 1*/
		use_multistage_wdt; /* Use FIQ debug watchdog */
	};

	abox_gic: abox_gic@0x17CF0000 {
		compatible = "samsung,abox_gic";
		reg = <0x0 0x17CF1000 0x1000>, <0x0 0x17CF2000 0x1004>;
		reg-names = "gicd", "gicc";
		interrupts = <0 INTREQ__ABOX_GIC400 0>;
	};

	abox: abox@0x17C50000 {
		compatible = "samsung,abox";
		reg = <0x0 0x17C50000 0x10000>, <0x0 0x17C10000 0x10000>, <0x0 0x17D00000 0x31000>;
		reg-names = "sfr", "sysreg", "sram";
		#address-cells = <2>;
		#size-cells = <1>;
		ranges;
		quirks = "try to asrc off";
		#sound-dai-cells = <1>;
		samsung,power-domain = <&pd_aud>;
		ipc_tx_offset = <0x30000>;
		ipc_rx_offset = <0x30300>;
		ipc_tx_ack_offset = <0x302FC>;
		ipc_rx_ack_offset = <0x305FC>;
		abox_gic = <&abox_gic>;
		clocks = <&clock PLL_OUT_AUD>, <&clock GATE_ABOX_DUMMY>,
			<&clock DOUT_CLK_ABOX_AUDIF>, <&clock DOUT_CLK_ABOX_DMIC>,
			<&clock DOUT_CLK_ABOX_ACLK>;
		clock-names = "pll", "cpu", "audif", "dmic", "bus";
		uaif_max_div = <512>;
		iommus = <&sysmmu_aud>;
		pm_qos_int = <0 0 0 0 0>;
		pm_qos_aud = <1180000 800000 590000 394000 0>;

		abox_rdma_0: abox_rdma@0x17C51000 {
			compatible = "samsung,abox-rdma";
			reg = <0x0 0x17C51000 0x100>;
			id = <0>;
			type = "normal";
			buffer_type = "dma";
		};

		abox_rdma_1: abox_rdma@0x17C51100 {
			compatible = "samsung,abox-rdma";
			reg = <0x0 0x17C51100 0x100>;
			id = <1>;
			type = "normal";
			buffer_type = "dma";
		};

		abox_rdma_2: abox_rdma@0x17C51200 {
			compatible = "samsung,abox-rdma";
			reg = <0x0 0x17C51200 0x100>;
			id = <2>;
			type = "normal";
			buffer_type = "dma";
		};

		abox_rdma_3: abox_rdma@0x17C51300 {
			compatible = "samsung,abox-rdma";
			reg = <0x0 0x17C51300 0x100>;
			id = <3>;
			type = "sync";
			buffer_type = "ion";
		};

		abox_rdma_4: abox_rdma@0x17C51400 {
			compatible = "samsung,abox-rdma";
			reg = <0x0 0x17C51400 0x100>;
			id = <4>;
			type = "call";
			buffer_type = "dma";
		};

		abox_rdma_5: abox_rdma@0x17C51500 {
			compatible = "samsung,abox-rdma";
			reg = <0x0 0x17C51500 0x100>, <0x0 0x17D30600 0x70>;
			id = <5>;
			type = "compress";
			buffer_type = "dma";
		};

		abox_rdma_6: abox_rdma@0x17C51600 {
			compatible = "samsung,abox-rdma";
			reg = <0x0 0x17C51600 0x100>;
			id = <6>;
			type = "realtime";
			buffer_type = "dma";
		};

		abox_rdma_7: abox_rdma@0x17C51700 {
			compatible = "samsung,abox-rdma";
			reg = <0x0 0x17C51700 0x100>;
			id = <7>;
			type = "realtime";
			buffer_type = "dma";
		};

		abox_wdma_0: abox_wdma@0x17C52000 {
			compatible = "samsung,abox-wdma";
			reg = <0x0 0x17C52000 0x100>;
			id = <0>;
			type = "realtime";
			buffer_type = "dma";
		};

		abox_wdma_1: abox_wdma@0x17C52100 {
			compatible = "samsung,abox-wdma";
			reg = <0x0 0x17C52100 0x100>;
			id = <1>;
			type = "normal";
			buffer_type = "ion";
		};

		abox_wdma_2: abox_wdma@0x17C52200 {
			compatible = "samsung,abox-wdma";
			reg = <0x0 0x17C52200 0x100>;
			id = <2>;
			type = "call";
			buffer_type = "dma";
		};

		abox_wdma_3: abox_wdma@0x17C52300 {
			compatible = "samsung,abox-wdma";
			reg = <0x0 0x17C52300 0x100>;
			id = <3>;
			type = "realtime";
			buffer_type = "dma";
		};

		abox_wdma_4: abox_wdma@0x17C52400 {
			compatible = "samsung,abox-wdma";
			reg = <0x0 0x17C52400 0x100>;
			id = <4>;
			type = "vi-sensing";
			buffer_type = "dma";
		};

		abox_uaif_0: abox_uaif@0x17C50500 {
			compatible = "samsung,abox-uaif";
			reg = <0x0 0x17C50500 0x10>;
			id = <0>;
			clocks = <&clock DOUT_CLK_ABOX_UAIF0>, <&clock GATE_ABOX_BCLK0>;
			clock-names = "bclk", "bclk_gate";
			pinctrl-names = "default", "sleep";
			pinctrl-0 = <&aud_i2s0_bus>;
			pinctrl-1 = <&aud_i2s0_idle>;
		};

		abox_uaif_1: abox_uaif@0x17C50510 {
			compatible = "samsung,abox-uaif";
			reg = <0x0 0x17C50510 0x10>;
			id = <1>;
			clocks = <&clock DOUT_CLK_ABOX_UAIF1>, <&clock GATE_ABOX_BCLK1>;
			clock-names = "bclk", "bclk_gate";
			pinctrl-names = "default", "sleep";
			pinctrl-0 = <&aud_i2s1_bus>;
			pinctrl-1 = <&aud_i2s1_idle>;
		};

		abox_uaif_2: abox_uaif@0x17C50520 {
			compatible = "samsung,abox-uaif";
			reg = <0x0 0x17C50520 0x10>;
			id = <2>;
			clocks = <&clock DOUT_CLK_ABOX_UAIF2>, <&clock GATE_ABOX_BCLK2>;
			clock-names = "bclk", "bclk_gate";
			pinctrl-names = "default", "sleep";
			pinctrl-0 = <&aud_i2s2_bus>;
			pinctrl-1 = <&aud_i2s2_idle>;
		};

		abox_uaif_3: abox_uaif@0x17C50530 {
			compatible = "samsung,abox-uaif";
			reg = <0x0 0x17C50530 0x10>;
			id = <3>;
			clocks = <&clock DOUT_CLK_ABOX_UAIF3>, <&clock GATE_ABOX_BCLK3>;
			clock-names = "bclk", "bclk_gate";
			pinctrl-names = "default", "sleep";
			pinctrl-0 = <&aud_i2s3_bus>;
			pinctrl-1 = <&aud_i2s3_idle>;
		};

		abox_dsif: abox_dsif@0x17C50550 {
			compatible = "samsung,abox-dsif";
			reg = <0x0 0x17C50550 0x10>;
			id = <5>;
			clocks = <&clock DOUT_CLK_ABOX_DSIF>, <&clock GATE_ABOX_BCLK_DSIF>;
			clock-names = "bclk", "bclk_gate";
			/* DSIF and UAIF2 shares GPIO
			 * pinctrl-names = "default", "sleep";
			 * pinctrl-0 = <&aud_dsd_bus>;
			 * pinctrl-1 = <&aud_dsd_idle>;
			 */
		};

		abox_effect: abox_effect@0x17D2E000 {
			compatible = "samsung,abox-effect";
			reg = <0x0 0x17D2E000 0x1000>;
			reg-names = "reg";
			abox = <&abox>;
		};

		abox_debug: abox_debug@0 {
			compatible = "samsung,abox-debug";
			memory-region = <&abox_rmem>;
			reg = <0x0 0x0 0x0>;
		};

		abox_vss: abox_vss@0 {
			compatible = "samsung,abox-vss";
			magic_offset = <0x600000>;
			reg = <0x0 0x0 0x0>;
		};

		ext_bin_0: ext_bin@0 {
			status = "disabled";
			samsung,name = "dsm.bin";
			samsung,area = <1>; /* 0:SRAM, 1:DRAM, 2:VSS */
			samsung,offset = <0x502000>;
		};
		ext_bin_1: ext_bin@1 {
			status = "okay";
			samsung,name = "AP_AUDIO_SLSI.bin";
			samsung,area = <1>;
			samsung,offset = <0x7E0000>;
		};
		ext_bin_2: ext_bin@2 {
			status = "okay";
			samsung,name = "APBargeIn_AUDIO_SLSI.bin";
			samsung,area = <1>;
			samsung,offset = <0x7DC000>;
		};
		ext_bin_3: ext_bin@3 {
			status = "disabled";
			samsung,name = "SoundBoosterParam.bin";
			samsung,area = <1>;
			samsung,offset = <0x4FC000>;
		};
		ext_bin_4: ext_bin@4 {
			status = "okay";
			samsung,name = "APDV_AUDIO_SLSI.bin";
			samsung,area = <1>;
			samsung,offset = <0x4D0000>;
		};
		ext_bin_5: ext_bin@5 {
			status = "okay";
			samsung,name = "APBiBF_AUDIO_SLSI.bin";
			samsung,area = <1>;
			samsung,offset = <0x7DF000>;
		};
		ext_bin_6: ext_bin@6 {
			status = "disabled";
			samsung,name = "dummy.bin";
			samsung,area = <1>;
			samsung,offset = <0x800000>;
		};
		ext_bin_7: ext_bin@7 {
			status = "disabled";
			samsung,name = "dummy.bin";
			samsung,area = <1>;
			samsung,offset = <0x800000>;
		};
	};

	schedutil {
		domain@0 {
			device_type = "freqvar-tune";
			shared-cpus = "0-3";

			boost_table = < 0 >;
			up_rate_limit_table = < 5000 >;
			down_rate_limit_table = < 5000 >;
			st_table = < 5 >;
		};

		domain@1 {
			device_type = "freqvar-tune";
			shared-cpus = "4-7";

			boost_table = < 0 >;
			up_rate_limit_table = < 5000 >;
			down_rate_limit_table = < 5000 >;
			st_table = < 5 >;
		};
	};

	cpu_hotplug {
		compatible = "exynos, cpu_hotplug";
		boot_lock_time = <40>;
		fast_hp_cpus = "5-7";
	};

	hotplug_governor {
		compatible = "exynos, hotplug_governor";

		single_change_ms = <30>;
		dual_change_ms = <30>;
		quad_change_ms = <15>;
		big_heavy_thr = <600>;
		lit_heavy_thr = <180>;
		big_idle_thr = <106>;
		lit_idle_thr = <46>;
		ldsum_heavy_thr = <800>;
		ldsum_enabled = <0>;
		skip_lit_enabled = <0>;
		cl_busy_ratio = <65>;
		/* single_freq is parsed from ECT */
		dual_freq = <2314000>;
		triple_freq = <1794000>;
		quad_freq = <1794000>;
		cal-id = <ACPM_DVFS_CPUCL1>;
	};

	schedutil_gov {
		schedutil_domain0: domain@0 {
			device_type = "schedutil-domain";
			shared-cpus = "0-3";

			enabled = <0>;          /* Disabled */
			qos_min_class = <3>;
		};

		schedutil_domain1: domain@1 {
			device_type = "schedutil-domain";
			shared-cpus = "4-7";

			enabled = <1>;          /* Enabled */
			expired_time = <80>;    /* 80ms */
			qos_min_class = <5>;
		};
	};
	
	cpuidle-ucc {

		ucc-config0 {
			index = <0>;
		};

		ucc-config1 {
			index = <1>;
			cstate = "4-7";
		};
	};

	cpufreq-ufc {
		/* Ctrl Type */
		#define PM_QOS_MIN_LIMIT		0
		#define PM_QOS_MIN_WO_BOOST_LIMIT	1
		#define PM_QOS_MAX_LIMIT		2
		/* Execution Mode */
		#define	AARCH64_MODE			0
		#define AARCH32_MODE			1

		device_type = "cpufreq_ufc";

		domain@0 {
			device_type = "cpufreq-userctrl";
			shared-cpus = "0-3";

			user-default-qos = <715000>;
			ucc-index = <0>;
		};

		domain@1 {
			device_type = "cpufreq-userctrl";
			shared-cpus = "4-7";

			user-default-qos = <962000>;
			ucc-index = <1>;

			min-limit {
				ctrl-type = <PM_QOS_MIN_LIMIT>;
				execution-mode = <AARCH64_MODE>;
					/* mngs	    ank */
				table = < 2886000 2002000
					  2860000 1950000
					  2704000 1794000
					  2652000 1690000
					  2496000 1456000
					  2314000 1456000
					  2106000 1053000
					  2002000  949000
					  1924000  949000
					  1794000  832000
					  1690000  832000
					  1586000  715000
					  1469000  715000
					  1261000  598000
					  1170000  598000
					  1066000  455000
					   962000  455000
					   858000  299000
					   741000  299000
					   650000  208000
					   598000  208000 >;
			};

			max-limit {
				ctrl-type = <PM_QOS_MAX_LIMIT>;
				execution-mode = <AARCH64_MODE>;
					/* mngs	    ank */
				table = < 2886000 2002000
					  2860000 2002000
					  2704000 2002000
					  2652000 2002000
					  2496000 2002000
					  2314000 2002000
					  2158000 2002000
					  2002000 2002000
					  1924000 1950000
					  1794000 1794000
					  1690000 1794000
					  1586000 1794000
					  1469000 1794000
					  1261000 1794000
					  1170000 1794000
					  1066000 1794000
					   962000 1794000
					   858000 1794000
					   741000 1794000
					   650000 1794000
					   598000 1794000 >;
			};

		};
	};

	cpufreq {
		cpufreq_domain0: domain@0 {
			device_type = "cpufreq-domain";
			sibling-cpus = "0-3";
			cal-id = <ACPM_DVFS_CPUCL0>;
			dm-type = <DM_CPU_CL0>;

			min-freq = <208000>;
			max-freq = <2002000>;

			/* PM QoS Class ID*/
			pm_qos-min-class = <3>;
			pm_qos-max-class = <4>;

			#cooling-cells = <2>; /* min followed by max */

			dm-constraints {
				mif-perf {
					const-type = <CONSTRAINT_MIN>;
					dm-type = <DM_MIF>;
						/*  cpu     mif  */
					table = < 2002000  1014000
						  1950000  1014000
						  1794000  845000
						  1690000  845000
						  1456000  676000
						  1248000  676000
						  1053000  676000
						   949000  676000
						   832000  546000
						   715000  546000
						   598000  421000
						   455000  421000
						   299000  421000
						   208000  421000
						   >;
				};
			};

			slack_timer {
				device_type = "slack-timer-domain";
				enabled = <0>;          /* Disabled */
			};
		};
		cpufreq_domain1: domain@1 {
			device_type = "cpufreq-domain";
			sibling-cpus = "4-7";
			cal-id = <ACPM_DVFS_CPUCL1>;
			dm-type = <DM_CPU_CL1>;

			min-freq = <598000>;
			max-freq = <1794000>;
			policy-max = <1794000>;

			/* PM QoS Class ID*/
			pm_qos-min-class = <5>;
			pm_qos-max-class = <6>;

			pm_qos-booting = <1794000>;

			#cooling-cells = <2>; /* min followed by max */

			dm-constraints {
				mif-perf {
					const-type = <CONSTRAINT_MIN>;
					dm-type = <DM_MIF>;
						/*  cpu     mif  */
					table = < 2886000 1794000
						  2860000 1794000
						  2704000 1794000
						  2652000 1794000
						  2496000 1794000
						  2314000 1794000
						  2106000 1794000
						  2002000 1794000
						  1924000 1794000
						  1794000 1794000
						  1690000 1539000
						  1586000 1014000
						  1469000  845000
						  1261000  676000
						  1170000  676000
						  1066000  676000
						   962000  546000
						   858000  546000
						   741000  421000
						   650000  421000
						   598000  421000 >;
				};
			};

			slack_timer {
				device_type = "slack-timer-domain";
				enabled = <1>;          /* Enabled */
				expired_time = <80>;    /* 80ms */
			};
		};
	};

	smc_info: mcinfo@1B8300000 {
		compatible = "samsung,exynos-mcinfo";
		reg =	<0x0 0x1B83004C 0x4>,
			<0x0 0x1B93004C 0x4>,
			<0x0 0x1BA3004C 0x4>,
			<0x0 0x1BB3004C 0x4>;
		bit_field = <20 4>;
		/* start bit, width */
		basecnt = <4>;
		irqcnt = <4>;

		interrupts = <0 INTREQ__DMC_TEMPERR_MIF0 0>,
			     <0 INTREQ__DMC_TEMPERR_MIF1 0>,
			     <0 INTREQ__DMC_TEMPERR_MIF2 0>,
			     <0 INTREQ__DMC_TEMPERR_MIF3 0>;
	};

	fimc_is: fimc_is@16290000 {
		compatible = "samsung,exynos5-fimc-is";
		#pb-id-cells = <6>;
		reg = <0x0 0x162F0000 0x100>, /* CSIS-DMA */
			<0x0 0x16290000 0x10000>, /* FIMC-3AA0 */
			<0x0 0x162A0000 0x10000>, /* FIMC-3AA1 */
			<0x0 0x16430000 0x10000>, /* FIMC_ISPLP */
			<0x0 0x16630000 0x10000>, /* FIMC_ISPHQ */
			<0x0 0x16440000 0x4000>, /* MC_SCALER */
			<0x0 0x16510000 0x10000>, /* FIMC-VRA (Set A) */
			<0x0 0x16520000 0x10000>, /* FIMC-VRA (Set B) */
			<0x0 0x16880000 0x10000>, /* DCP */
			<0x0 0x163A0000 0x100>; /* PDP_STAT_DMA */
		interrupts = <0 INTREQ__TAAM_0 0>, /* 3AA0_0 */
			<0 INTREQ__TAAM_1 0>, /* 3AA0_1 */
			<0 INTREQ__TAA_0 0>, /* 3AA1_0 */
			<0 INTREQ__TAA_1 0>, /* 3AA1_1 */
			<0 INTREQ__ISPLP_0 0>, /* ISPLP_0 */
			<0 INTREQ__ISPLP_1 0>, /* ISPLP_1 */
			<0 INTREQ__BLK_ISPHQ_ISPHQ_INTREQ0 0>, /* ISPHQ_0 */
			<0 INTREQ__BLK_ISPHQ_ISPHQ_INTREQ1 0>, /* ISPHQ_1 */
			<0 INTREQ__MC_SCALER_0 0>, /* MC_SC_0 */
			<0 INTREQ__MC_SCALER_1 0>, /* MC_SC_1 */
			<0 INTREQ__VRA 0>, /* VRA_1 */
			<0 INTREQ_BLK_DCRD_DCP_IntReq_0 0>, /* DCP_0 */
			<0 INTREQ_BLK_DCRD_DCP_IntReq_1 0>; /* DCP_1 */
		pinctrl-names = "default","release";
		pinctrl-0 = <>;
		pinctrl-1 = <>;
		samsung,power-domain = <&pd_isplp>;
		clocks = <&clock GATE_IS_ISPHQ>,
			<&clock GATE_IS_ISPHQ_C2COM>,
			<&clock UMUX_CLKCMU_ISPHQ_BUS>,

			<&clock GATE_IS_ISPLP_MC_SCALER>,
			<&clock GATE_IS_ISPLP>,
			<&clock GATE_IS_ISPLP_VRA>,
			<&clock GATE_IS_ISPLP_GDC>,
			<&clock GATE_IS_ISPLP_C2>,
			<&clock UMUX_CLKCMU_ISPLP_BUS>,
			<&clock UMUX_CLKCMU_ISPLP_VRA>,
			<&clock UMUX_CLKCMU_ISPLP_GDC>,

			<&clock GATE_IS_ISPPRE_CSIS0>,
			<&clock GATE_IS_ISPPRE_CSIS1>,
			<&clock GATE_IS_ISPPRE_CSIS2>,
			<&clock GATE_IS_ISPPRE_CSIS3>,
			<&clock GATE_IS_ISPPRE_PDP_DMA>,
			<&clock GATE_IS_ISPPRE_3AA>,
			<&clock GATE_IS_ISPPRE_3AAM>,
			<&clock GATE_IS_ISPPRE_PDP_CORE0>,
			<&clock GATE_IS_ISPPRE_PDP_CORE1>,
			<&clock UMUX_CLKCMU_ISPPRE_BUS>,

			<&clock CIS_CLK0>,
			<&clock CIS_CLK1>,
			<&clock CIS_CLK2>,
			<&clock CIS_CLK3>,

			<&clock GATE_DFTMUX_TOP_CIS_CLK0>,
			<&clock GATE_DFTMUX_TOP_CIS_CLK1>,
			<&clock GATE_DFTMUX_TOP_CIS_CLK2>,
			<&clock GATE_DFTMUX_TOP_CIS_CLK3>;
		clock-names = "GATE_IS_ISPHQ",
			"GATE_IS_ISPHQ_C2COM",
			"UMUX_CLKCMU_ISPHQ_BUS",

			"GATE_IS_ISPLP_MC_SCALER",
			"GATE_IS_ISPLP",
			"GATE_IS_ISPLP_VRA",
			"GATE_IS_ISPLP_GDC",
			"GATE_IS_ISPLP_C2",
			"UMUX_CLKCMU_ISPLP_BUS",
			"UMUX_CLKCMU_ISPLP_VRA",
			"UMUX_CLKCMU_ISPLP_GDC",

			"GATE_IS_ISPPRE_CSIS0",
			"GATE_IS_ISPPRE_CSIS1",
			"GATE_IS_ISPPRE_CSIS2",
			"GATE_IS_ISPPRE_CSIS3",
			"GATE_IS_ISPPRE_PDP_DMA",
			"GATE_IS_ISPPRE_3AA",
			"GATE_IS_ISPPRE_3AAM",
			"GATE_IS_ISPPRE_PDP_CORE0",
			"GATE_IS_ISPPRE_PDP_CORE1",
			"UMUX_CLKCMU_ISPPRE_BUS",

			"CIS_CLK0",
			"CIS_CLK1",
			"CIS_CLK2",
			"CIS_CLK3",

			"MUX_CIS_CLK0",
			"MUX_CIS_CLK1",
			"MUX_CIS_CLK2",
			"MUX_CIS_CLK3";
		status = "ok";
		iommus = <&sysmmu_isppre>, <&sysmmu_isplp0>, <&sysmmu_isplp1>, <&sysmmu_isphq>;
		#cooling-cells = <2>; /* min followed by max */
		ewf-index = <EWF_CMU_BUSC>;
	};

	camerapp_gdc: gdc@16530000 {
		compatible = "samsung,exynos5-camerapp-gdc";
		#pb-id-cells = <6>;
		reg = <0x0 0x16530000 0x10000>; /* GDC */
		interrupts = <0 INTREQ__GDC 0>; /* GDC */
		pinctrl-names = "default","release";
		pinctrl-0 = <>;
		pinctrl-1 = <>;
		samsung,power-domain = <&pd_isplp>;
		clocks = <&clock GATE_IS_ISPLP_GDC>,
			<&clock UMUX_CLKCMU_ISPLP_GDC>;
		clock-names = "gate",
			"gate2";
		status = "ok";
		iommus = <&sysmmu_isplp0>;
		#cooling-cells = <2>; /* min followed by max */
	};

	mipi_phy_csis0_m4s4_top: dphy_m4s4_csis0@0x16210500 {
		/* DCPHY 4.5 Gbps 4lane */
		compatible = "samsung,mipi-phy-m4s4-top";
		samsung,pmu-syscon = <&pmu_system_controller>;
		isolation = <0x70C>; /* PMU address offset */
		reg = <0x0 0x16210500 0x4>; /* SYSREG address for reset */
		reset = <0>; /* reset bit */
		owner = <1>; /* 0: DSI,  1: CSI */
		#phy-cells = <1>;
	};

	mipi_phy_csis2_m4s4_mod: dphy_m4s4_csis2@0x16210500 {
		/* DCPHY 4.5 Gbps 4lane */
		compatible = "samsung,mipi-phy-m4s4-mod";
		samsung,pmu-syscon = <&pmu_system_controller>;
		isolation = <0x710>; /* PMU address offset */
		reset = <1>; /* reset bit */
		owner = <1>; /* 0: DSI,  1: CSI */
		#phy-cells = <1>;
	};

	mipi_phy_csis1_m0s4s2: dphy_m0s4s2_csis1@0x16210500 {
		/* DPHY 2.5 Gbps 4lane */
		compatible = "samsung,mipi-phy-m1s2s2";
		samsung,pmu-syscon = <&pmu_system_controller>;
		isolation = <0x730>; /* PMU address offset */
		reset = <2>; /* reset bit */
		owner = <1>; /* 0: DSI,  1: CSI */
		#phy-cells = <1>;
	};

	mipi_phy_csis3_m0s4s2: dphy_m0s4s2_csis3@0x16210500 {
		/* DPHY 2.5 Gbps 2lane */
		compatible = "samsung,mipi-phy-m1s2s2";
		samsung,pmu-syscon = <&pmu_system_controller>;
		isolation = <0x730>; /* PMU address offset */
		reset = <3>; /* reset bit */
		owner = <1>; /* 0: DSI,  1: CSI */
		#phy-cells = <1>;
	};

	fimc_is_sensor0: fimc_is_sensor@16230000 {
		/* REAR/CSIS0 */
		compatible = "samsung,exynos5-fimc-is-sensor";
		#pb-id-cells = <4>;
		reg = <0x0 0x16230000 0x1000>, /* MIPI-CSI0 */
			<0x0 0x16160000 0x10000>, /* PHY: TOP_M4S4 */

			<0x0 0x162B0000 0x100>, /* VC0 DMA0 */
			<0x0 0x162B0400 0x100>, /* VC0 DMA0 COMMON */
			<0x0 0x162B0100 0x100>, /* VC1 DMA0 */
			<0x0 0x162B0400 0x100>, /* VC1 DMA0 COMMON */
			<0x0 0x162B0200 0x100>, /* VC2 DMA0 */
			<0x0 0x162B0400 0x100>, /* VC2 DMA0 COMMON */
			<0x0 0x162B0300 0x100>, /* VC3 DMA0 */
			<0x0 0x162B0400 0x100>, /* VC3 DMA0 COMMON */

			<0x0 0x162B0000 0x100>, /* VC0 DMA0 */
			<0x0 0x162B0400 0x100>, /* VC0 DMA0 COMMON */
			<0x0 0x16380000 0x100>, /* VC0 DMA4 */
			<0x0 0x16380400 0x100>, /* VC0 DMA4 COMMON */
			<0x0 0x16380100 0x100>, /* VC1 DMA4 */
			<0x0 0x16380400 0x100>, /* VC1 DMA4 COMMON */
			<0x0 0x16380200 0x100>, /* NOTHING */
			<0x0 0x16380400 0x100>; /* NOTHING */
		interrupts = <0 INTREQ__CSIS0 0>, /* MIPI-CSI0 */
			<0 INTREQ__CSIS0_PDP_DMA 0>, /* VC0 DMA0 */
			<0 INTREQ__CSIS0_PDP_DMA 0>, /* VC1 DMA0 */
			<0 INTREQ__CSIS0_PDP_DMA 0>, /* VC2 DMA0 */
			<0 INTREQ__CSIS0_PDP_DMA 0>, /* VC3 DMA0 */

			<0 INTREQ__CSIS0_PDP_DMA 0>, /* VC0 DMA0 */
			<0 INTREQ__PDP0_STAT_DMA 0>, /* VC0 DMA4 */
			<0 INTREQ__PDP0_STAT_DMA 0>, /* VC1 DMA4 */
			<0 INTREQ__PDP0_STAT_DMA 0>; /* NOTHING */
		samsung,power-domain = <&pd_isppre>;
		phys = <&mipi_phy_csis0_m4s4_top 0>;
		phy-names = "csis_dphy";
		clocks = <&clock CIS_CLK0>,
			<&clock CIS_CLK1>,
			<&clock CIS_CLK2>,
			<&clock CIS_CLK3>,

			<&clock GATE_DFTMUX_TOP_CIS_CLK0>,
			<&clock GATE_DFTMUX_TOP_CIS_CLK1>,
			<&clock GATE_DFTMUX_TOP_CIS_CLK2>,
			<&clock GATE_DFTMUX_TOP_CIS_CLK3>,

			<&clock GATE_IS_ISPPRE_CSIS0>,
			<&clock GATE_IS_ISPPRE_CSIS1>,
			<&clock GATE_IS_ISPPRE_CSIS2>,
			<&clock GATE_IS_ISPPRE_CSIS3>;
		clock-names = "CIS_CLK0",
			"CIS_CLK1",
			"CIS_CLK2",
			"CIS_CLK3",

			"MUX_CIS_CLK0",
			"MUX_CIS_CLK1",
			"MUX_CIS_CLK2",
			"MUX_CIS_CLK3",

			"GATE_IS_ISPPRE_CSIS0",
			"GATE_IS_ISPPRE_CSIS1",
			"GATE_IS_ISPPRE_CSIS2",
			"GATE_IS_ISPPRE_CSIS3";
		iommus = <&sysmmu_isppre>;
	};

	fimc_is_sensor1: fimc_is_sensor@16240000 {
		/* FRONT/CSIS0 */
		compatible = "samsung,exynos5-fimc-is-sensor";
		#pb-id-cells = <4>;
		reg = <0x0 0x16240000 0x1000>, /* MIPI-CSI0 */
			<0x0 0x16180000 0x10000>, /* PHY: MODULE_M0S4S2(S4) */

			<0x0 0x162C0000 0x100>, /* VC0 DMA1 */
			<0x0 0x162C0400 0x100>, /* VC0 DMA1 COMMON */
			<0x0 0x162C0100 0x100>, /* VC1 DMA1 */
			<0x0 0x162C0400 0x100>, /* VC1 DMA1 COMMON */
			<0x0 0x162C0200 0x100>, /* VC2 DMA1 */
			<0x0 0x162C0400 0x100>, /* VC2 DMA1 COMMON */
			<0x0 0x162C0300 0x100>, /* VC3 DMA1 */
			<0x0 0x162C0400 0x100>; /* VC3 DMA1 COMMON */
		interrupts = <0 INTREQ__CSIS1 0>, /* MIPI-CSI1 */
			<0 INTREQ__CSIS1_PDP_DMA 0>, /* VC0 DMA1 */
			<0 INTREQ__CSIS1_PDP_DMA 0>, /* VC1 DMA1 */
			<0 INTREQ__CSIS1_PDP_DMA 0>, /* VC2 DMA1 */
			<0 INTREQ__CSIS1_PDP_DMA 0>; /* VC3 DMA1 */
		samsung,power-domain = <&pd_isppre>;
		phys = <&mipi_phy_csis1_m0s4s2 0>;
		phy-names = "csis_dphy";
		clocks = <&clock CIS_CLK0>,
			<&clock CIS_CLK1>,
			<&clock CIS_CLK2>,
			<&clock CIS_CLK3>,

			<&clock GATE_DFTMUX_TOP_CIS_CLK0>,
			<&clock GATE_DFTMUX_TOP_CIS_CLK1>,
			<&clock GATE_DFTMUX_TOP_CIS_CLK2>,
			<&clock GATE_DFTMUX_TOP_CIS_CLK3>,

			<&clock GATE_IS_ISPPRE_CSIS0>,
			<&clock GATE_IS_ISPPRE_CSIS1>,
			<&clock GATE_IS_ISPPRE_CSIS2>,
			<&clock GATE_IS_ISPPRE_CSIS3>;
		clock-names = "CIS_CLK0",
			"CIS_CLK1",
			"CIS_CLK2",
			"CIS_CLK3",

			"MUX_CIS_CLK0",
			"MUX_CIS_CLK1",
			"MUX_CIS_CLK2",
			"MUX_CIS_CLK3",

			"GATE_IS_ISPPRE_CSIS0",
			"GATE_IS_ISPPRE_CSIS1",
			"GATE_IS_ISPPRE_CSIS2",
			"GATE_IS_ISPPRE_CSIS3";
		iommus = <&sysmmu_isppre>;
	};

	fimc_is_sensor2: fimc_is_sensor@16250000 {
		/* REAR_SUB/CSIS2 */
		compatible = "samsung,exynos5-fimc-is-sensor";
		#pb-id-cells = <4>;
		reg = <0x0 0x16250000 0x1000>, /* MIPI-CSI0 */
			<0x0 0x16170000 0x10000>, /* PHY: MODULE_M4S4*/

			<0x0 0x162D0000 0x100>, /* VC0 DMA2 */
			<0x0 0x162D0400 0x100>, /* VC0 DMA2 COMMON */
			<0x0 0x162D0100 0x100>, /* VC1 DMA2 */
			<0x0 0x162D0400 0x100>, /* VC1 DMA2 COMMON */
			<0x0 0x162D0200 0x100>, /* VC2 DMA2 */
			<0x0 0x162D0400 0x100>, /* VC2 DMA2 COMMON */
			<0x0 0x162D0300 0x100>, /* VC3 DMA2 */
			<0x0 0x162D0400 0x100>; /* VC3 DMA2 COMMON */
		interrupts = <0 INTREQ__CSIS2 0>, /* MIPI-CSI2 */
			<0 INTREQ__CSIS2_PDP_DMA 0>, /* VC0 DMA2 */
			<0 INTREQ__CSIS2_PDP_DMA 0>, /* VC1 DMA2 */
			<0 INTREQ__CSIS2_PDP_DMA 0>, /* VC2 DMA2 */
			<0 INTREQ__CSIS2_PDP_DMA 0>; /* VC3 DMA2 */
		samsung,power-domain = <&pd_isppre>;
		phys = <&mipi_phy_csis2_m4s4_mod 0>;
		phy-names = "csis_dphy";
		clocks = <&clock CIS_CLK0>,
			<&clock CIS_CLK1>,
			<&clock CIS_CLK2>,
			<&clock CIS_CLK3>,

			<&clock GATE_DFTMUX_TOP_CIS_CLK0>,
			<&clock GATE_DFTMUX_TOP_CIS_CLK1>,
			<&clock GATE_DFTMUX_TOP_CIS_CLK2>,
			<&clock GATE_DFTMUX_TOP_CIS_CLK3>,

			<&clock GATE_IS_ISPPRE_CSIS0>,
			<&clock GATE_IS_ISPPRE_CSIS1>,
			<&clock GATE_IS_ISPPRE_CSIS2>,
			<&clock GATE_IS_ISPPRE_CSIS3>;
		clock-names = "CIS_CLK0",
			"CIS_CLK1",
			"CIS_CLK2",
			"CIS_CLK3",

			"MUX_CIS_CLK0",
			"MUX_CIS_CLK1",
			"MUX_CIS_CLK2",
			"MUX_CIS_CLK3",

			"GATE_IS_ISPPRE_CSIS0",
			"GATE_IS_ISPPRE_CSIS1",
			"GATE_IS_ISPPRE_CSIS2",
			"GATE_IS_ISPPRE_CSIS3";
		iommus = <&sysmmu_isppre>;
	};

	fimc_is_sensor3: fimc_is_sensor@16260000 {
		/* IRIS/CSIS3 */
		compatible = "samsung,exynos5-fimc-is-sensor";
		#pb-id-cells = <4>;
		reg = <0x0 0x16260000 0x1000>, /* MIPI-CSI0 */
			<0x0 0x16190000 0x10000>, /* PHY: MODULE_M0S4S2(S2) */

			<0x0 0x162E0000 0x100>, /* VC0 DMA3 */
			<0x0 0x162E0400 0x100>, /* VC0 DMA3 COMMON */
			<0x0 0x162E0100 0x100>, /* VC1 DMA3 */
			<0x0 0x162E0400 0x100>, /* VC1 DMA3 COMMON */
			<0x0 0x162E0200 0x100>, /* VC2 DMA3 */
			<0x0 0x162E0400 0x100>, /* VC2 DMA3 COMMON */
			<0x0 0x162E0300 0x100>, /* VC3 DMA3 */
			<0x0 0x162E0400 0x100>; /* VC3 DMA3 COMMON */
		interrupts = <0 INTREQ__CSIS3 0>, /* MIPI-CSI3 */
			<0 INTREQ__CSIS3_PDP_DMA 0>, /* VC0 DMA3 */
			<0 INTREQ__CSIS3_PDP_DMA 0>, /* VC1 DMA3 */
			<0 INTREQ__CSIS3_PDP_DMA 0>, /* VC2 DMA3 */
			<0 INTREQ__CSIS3_PDP_DMA 0>; /* VC3 DMA3 */
		samsung,power-domain = <&pd_isppre>;
		phys = <&mipi_phy_csis3_m0s4s2 0>;
		phy-names = "csis_dphy";
		clocks = <&clock CIS_CLK0>,
			<&clock CIS_CLK1>,
			<&clock CIS_CLK2>,
			<&clock CIS_CLK3>,

			<&clock GATE_DFTMUX_TOP_CIS_CLK0>,
			<&clock GATE_DFTMUX_TOP_CIS_CLK1>,
			<&clock GATE_DFTMUX_TOP_CIS_CLK2>,
			<&clock GATE_DFTMUX_TOP_CIS_CLK3>,

			<&clock GATE_IS_ISPPRE_CSIS0>,
			<&clock GATE_IS_ISPPRE_CSIS1>,
			<&clock GATE_IS_ISPPRE_CSIS2>,
			<&clock GATE_IS_ISPPRE_CSIS3>;
		clock-names = "CIS_CLK0",
			"CIS_CLK1",
			"CIS_CLK2",
			"CIS_CLK3",

			"MUX_CIS_CLK0",
			"MUX_CIS_CLK1",
			"MUX_CIS_CLK2",
			"MUX_CIS_CLK3",

			"GATE_IS_ISPPRE_CSIS0",
			"GATE_IS_ISPPRE_CSIS1",
			"GATE_IS_ISPPRE_CSIS2",
			"GATE_IS_ISPPRE_CSIS3";
		iommus = <&sysmmu_isppre>;
	};

	fimc_is_pdp0: fimc_is_pdp@16270000 {
		/* PDP CORE0 */
		compatible = "samsung,exynos5-fimc-is-pdp";
		reg = <0x0 0x16270000 0x2000>; /* PDP CORE0 */
		interrupts = <0 INTREQ__PDP_CORE0 0>;
		id = <0>;
	};

	fimc_is_pdp1: fimc_is_pdp@16280000 {
		/* PDP CORE1 */
		compatible = "samsung,exynos5-fimc-is-pdp";
		interrupts = <0 INTREQ__PDP_CORE1 0>;
		reg = <0x0 0x16280000 0x2000>; /* PDP CORE1 */
		id = <1>;
	};

	pcie0@116A0000 {
		compatible = "samsung,exynos-pcie";
		gpios = <&gpf2 2 0x1 /* PERST */>;
		reg = <0x0 0x116A0000 0x1000    /* elbi base */
			0x0 0x116D0000 0x1000   /* phy base */
			0x0 0x11411044 0x10     /* sysreg base */
			0x0 0x11700000 0x1000   /* DBI base */
			0x0 0x116C0000 0x1FC    /* phy pcs base */
			0x0 0x127FE000 0x2000   /* configuration space */
			0x0 0x11680000 0x1000>; /* I/A space */
		reg-names = "elbi", "phy", "sysreg", "dbi", "pcs", "config", "ia";
		interrupts = <0 INTREQ__PCIE_WIFI0 0>; /* IRQ_PULSE */
		samsung,syscon-phandle = <&pmu_system_controller>;
		samsung,sysreg-phandle = <&sysreg_fsys1_controller>;
		clocks = <&clock GATE_PCIE_GEN2_MSTR>;
		pinctrl-names = "default";
		pinctrl-0 = <&pcie0_clkreq &pcie0_perst &pcie_wake>;
		#address-cells = <3>;
		#size-cells = <2>;
		device_type = "pci";
		/* non-prefetchable memory */
		ranges = <0x82000000 0 0x11800000 0 0x11800000 0 0xFF0000>;
		/* ranges = <0x82000000 0 0x20000000 0 0x20000000 0 0x20000000>; */
		#interrupt-cells = <1>;
		interrupt-map-mask = <0 0 0 0>;
		interrupt-map = <0 0 0 0 &gic 0 253 0x4>;
		ip-ver = <0x981000>;
		num-lanes = <1>;
		ch-num = <0>;
		pcie-clk-num = <0>;
		phy-clk-num = <0>;
		pcie-pm-qos-int = <0>;
		use-cache-coherency = "false";
		use-msi = "false";
		use-sicd = "true";
		use-sysmmu = "false";
		use-ia = "true";
		max-link-speed = <LINK_SPEED_GEN2>;
		status = "disabled";
	};

	pcie1@116B0000 {
		compatible = "samsung,exynos-pcie";
		gpios = <&gpf2 5 0x1 /* PERST */>;
		reg = <0x0 0x116B0000 0x1000    /* elbi base */
			0x0 0x116F0000 0x1000   /* phy base */
			0x0 0x11411054 0x10     /* sysreg base */
			0x0 0x11710000 0x1000   /* DBI base */
			0x0 0x116E0000 0x1FC    /* phy pcs base */
			0x0 0x137FE000 0x2000>; /* configuration space */
		reg-names = "elbi", "phy", "sysreg", "dbi", "pcs", "config";
		interrupts = <0 INTREQ__PCIE_WIFI1 0>; /* IRQ_PULSE */
		samsung,syscon-phandle = <&pmu_system_controller>;
		clocks = <&clock GATE_PCIE_GEN3_MSTR>;
		pinctrl-names = "default";
		pinctrl-0 = <&pcie1_clkreq &pcie1_perst>;
		#address-cells = <3>;
		#size-cells = <2>;
		device_type = "pci";
		/* non-prefetchable memory */
		ranges = <0x82000000 0 0x12800000 0 0x12800000 0 0xFF0000>;
		/* ranges = <0x82000000 0 0x40000000 0 0x40000000 0 0x20000000>; */
		#interrupt-cells = <1>;
		interrupt-map-mask = <0 0 0 0>;
		interrupt-map = <0 0 0 0 &gic 0 254 0x4>;
		ip-ver = <0x981000>;
		num-lanes = <1>;
		ch-num = <1>;
		pcie-clk-num = <0>;
		phy-clk-num = <0>;
		pcie-pm-qos-int = <0>;
		use-cache-coherency = "false";
		use-msi = "false";
		use-sicd = "true";
		use-sysmmu = "false";
		max-link-speed = <LINK_SPEED_GEN3>;
		status = "disabled";
	};

	mailbox_vts: mailbox@0x141B0000 {
		compatible = "samsung,mailbox-asoc";
		reg = <0x0 0x141B0000 0x10000>;
		reg-names = "sfr";
		interrupts = <0 INTREQ__MAILBOX_VTS2AP 0>;
		interrupt-controller;
		#interrupt-cells = <1>;
	};

	vts: vts@0x13870000 {
		compatible = "samsung,vts";
		reg = <0x0 0x13810000 0x1000>, <0x0 0x13B00000 0x10010>, <0x0 0x13870000 0x8>, <0x0 0x13900000 0x67070>,
			 <0x0 0x138F0000 0x50>;
		reg-names = "sfr", "baaw", "dmic", "sram", "gpr";
		pinctrl-names = "dmic_default", "amic_default", "idle";
		pinctrl-0 = <&dmic_bus_clk &dmic_pdm>;
		pinctrl-1 = <&amic_bus_clk &amic_pdm>;
		pinctrl-2 = <&mic_bus_clk_idle &dmic_pdm_idle &amic_pdm_idle>;
		samsung,power-domain = <&pd_vts>;
		clocks = <&clock DOUT_CLK_VTS_DMIC>,
			<&clock DOUT_CLK_VTS_DMICIF>, <&clock DOUT_CLK_VTS_DMIC_DIV2>;
		clock-names = "dmic", "dmic_if", "dmic_sync";
		mailbox = <&mailbox_vts>;
		#sound-dai-cells = <1>;
		interrupt-parent = <&mailbox_vts>;
		interrupts = <10>, <11>, <12>, <13>, <14>, <15>, <16>, <17>, <18>, <19>;
		interrupt-names = "error", "boot_completed", "ipc_received", "voice_triggered",
				"trigger_period_elapsed", "record_period_elapsed", "debuglog_bufzero", "debuglog_bufone", "audio_dump", "log_dump";
	};

	vts_dma0: vts_dma0 {
		compatible = "samsung,vts-dma";
		vts = <&vts>;
		id = <0>;
		type = "vts-trigger";
	};

	vts_dma1: vts_dma1 {
		compatible = "samsung,vts-dma";
		vts = <&vts>;
		id = <1>;
		type = "vts-record";
	};

	cmu_ewf {
		compatible = "samsung,exynos-cmuewf";
		#address-cells = <2>;
		#size-cells = <1>;
		reg = <0x0 0x1A240000 0x1000>;
	};
};
